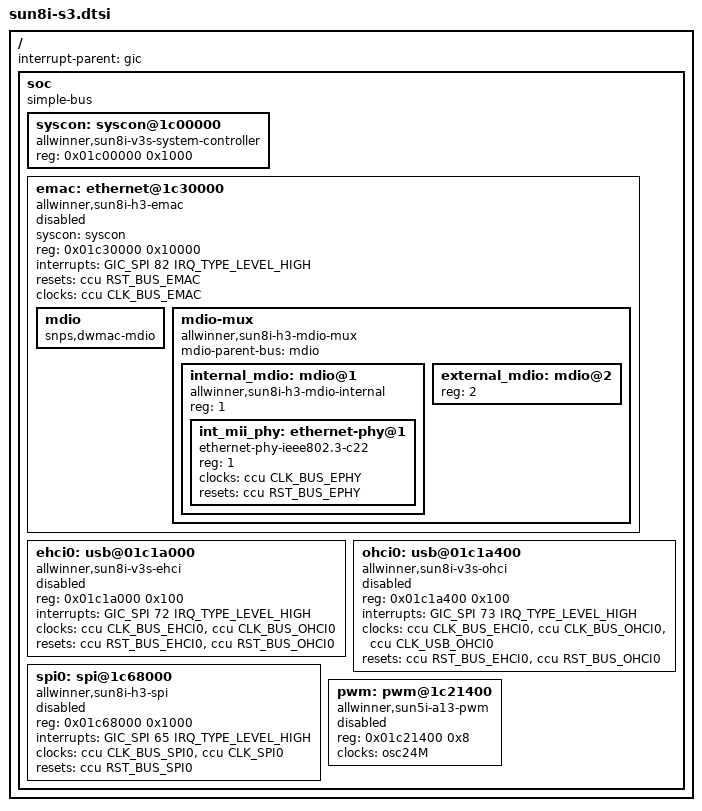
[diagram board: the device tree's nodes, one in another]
/*
 * Copyright (C) 2020 Aodzip <aodzip@gmail.com>
 *
 * This file is dual-licensed: you can use it either under the terms
 * of the GPL or the X11 license, at your option. Note that this dual
 * licensing only applies to this file, and not this project as a
 * whole.
 *
 *  a) This file is free software; you can redistribute it and/or
 *     modify it under the terms of the GNU General Public License as
 *     published by the Free Software Foundation; either version 2 of the
 *     License, or (at your option) any later version.
 *
 *     This file is distributed in the hope that it will be useful,
 *     but WITHOUT ANY WARRANTY; without even the implied warranty of
 *     MERCHANTABILITY or FITNESS FOR A PARTICULAR PURPOSE.  See the
 *     GNU General Public License for more details.
 *
 * Or, alternatively,
 *
 *  b) Permission is hereby granted, free of charge, to any person
 *     obtaining a copy of this software and associated documentation
 *     files (the "Software"), to deal in the Software without
 *     restriction, including without limitation the rights to use,
 *     copy, modify, merge, publish, distribute, sublicense, and/or
 *     sell copies of the Software, and to permit persons to whom the
 *     Software is furnished to do so, subject to the following
 *     conditions:
 *
 *     The above copyright notice and this permission notice shall be
 *     included in all copies or substantial portions of the Software.
 *
 *     THE SOFTWARE IS PROVIDED "AS IS", WITHOUT WARRANTY OF ANY KIND,
 *     EXPRESS OR IMPLIED, INCLUDING BUT NOT LIMITED TO THE WARRANTIES
 *     OF MERCHANTABILITY, FITNESS FOR A PARTICULAR PURPOSE AND
 *     NONINFRINGEMENT. IN NO EVENT SHALL THE AUTHORS OR COPYRIGHT
 *     HOLDERS BE LIABLE FOR ANY CLAIM, DAMAGES OR OTHER LIABILITY,
 *     WHETHER IN AN ACTION OF CONTRACT, TORT OR OTHERWISE, ARISING
 *     FROM, OUT OF OR IN CONNECTION WITH THE SOFTWARE OR THE USE OR
 *     OTHER DEALINGS IN THE SOFTWARE.
 */
/dts-v1/;
#include "sun8i-v3s.dtsi"
#include "sunxi-common-regulators.dtsi"
#include <dt-bindings/input/input.h>

/ {
    #address-cells = <1>;
    #size-cells = <1>;
    interrupt-parent = <&gic>;
    
    soc {
        compatible = "simple-bus";
        #address-cells = <1>;
        #size-cells = <1>;
        ranges;

        syscon: syscon@1c00000 {
            compatible = "allwinner,sun8i-v3s-system-controller", "allwinner,sun8i-h3-system-control", "syscon";
            reg = <0x01c00000 0x1000>;
        };

        emac: ethernet@1c30000 {
            compatible = "allwinner,sun8i-h3-emac";
            syscon = <&syscon>;
            reg = <0x01c30000 0x10000>;
            interrupts = <GIC_SPI 82 IRQ_TYPE_LEVEL_HIGH>;
            interrupt-names = "macirq";
            resets = <&ccu RST_BUS_EMAC>;
            reset-names = "stmmaceth";
            clocks = <&ccu CLK_BUS_EMAC>;
            clock-names = "stmmaceth";
            status = "disabled";

            mdio: mdio {
                #address-cells = <1>;
                #size-cells = <0>;
                compatible = "snps,dwmac-mdio";
            };

            mdio-mux {
                compatible = "allwinner,sun8i-h3-mdio-mux";
                #address-cells = <1>;
                #size-cells = <0>;

                mdio-parent-bus = <&mdio>;
                /* Only one MDIO is usable at the time */
                internal_mdio: mdio@1 {
                    compatible = "allwinner,sun8i-h3-mdio-internal";
                    reg = <1>;
                    #address-cells = <1>;
                    #size-cells = <0>;

                    int_mii_phy: ethernet-phy@1 {
                        compatible = "ethernet-phy-ieee802.3-c22";
                        reg = <1>;
                        clocks = <&ccu CLK_BUS_EPHY>;
                        resets = <&ccu RST_BUS_EPHY>;
                    };
                };

                external_mdio: mdio@2 {
                    reg = <2>;
                    #address-cells = <1>;
                    #size-cells = <0>;
                };
            };
        };

        ehci0: usb@01c1a000 {
            compatible = "allwinner,sun8i-v3s-ehci", "generic-ehci";
            reg = <0x01c1a000 0x100>;
            interrupts = <GIC_SPI 72 IRQ_TYPE_LEVEL_HIGH>;
            clocks = <&ccu CLK_BUS_EHCI0>, <&ccu CLK_BUS_OHCI0>;
            resets = <&ccu RST_BUS_EHCI0>, <&ccu RST_BUS_OHCI0>;
            status = "disabled";
        };

        ohci0: usb@01c1a400 {
            compatible = "allwinner,sun8i-v3s-ohci", "generic-ohci";
            reg = <0x01c1a400 0x100>;
            interrupts = <GIC_SPI 73 IRQ_TYPE_LEVEL_HIGH>;
            clocks = <&ccu CLK_BUS_EHCI0>, <&ccu CLK_BUS_OHCI0>, <&ccu CLK_USB_OHCI0>;
            resets = <&ccu RST_BUS_EHCI0>, <&ccu RST_BUS_OHCI0>;
            status = "disabled";
        };

        spi0: spi@1c68000 {
            compatible = "allwinner,sun8i-h3-spi";
            reg = <0x01c68000 0x1000>;
            interrupts = <GIC_SPI 65 IRQ_TYPE_LEVEL_HIGH>;
            clocks = <&ccu CLK_BUS_SPI0>, <&ccu CLK_SPI0>;
            clock-names = "ahb", "mod";
            resets = <&ccu RST_BUS_SPI0>;
            status = "disabled";
            #address-cells = <1>;
            #size-cells = <0>;
        };

        pwm: pwm@1c21400 {
            compatible = "allwinner,sun5i-a13-pwm";
            reg = <0x01c21400 0x8>;
            clocks = <&osc24M>;
            #pwm-cells = <3>;
            status = "disabled";
        };
    };
};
